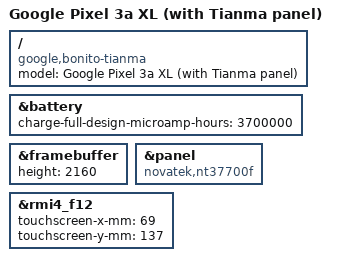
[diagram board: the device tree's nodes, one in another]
// SPDX-License-Identifier: GPL-2.0-only
/*
 * Device tree for Google Pixel 3a XL with the Tianma panel.
 *
 * Copyright (c) Richard Acayan. All rights reserved.
 */

/dts-v1/;

#include "sdm670-google-common.dtsi"

/ {
	model = "Google Pixel 3a XL (with Tianma panel)";
	compatible = "google,bonito-tianma", "google,bonito", "qcom,sdm670";
};

&battery {
	charge-full-design-microamp-hours = <3700000>;
};

&framebuffer {
	height = <2160>;
};

&panel {
	compatible = "novatek,nt37700f";
};

&rmi4_f12 {
	touchscreen-x-mm = <69>;
	touchscreen-y-mm = <137>;
};
